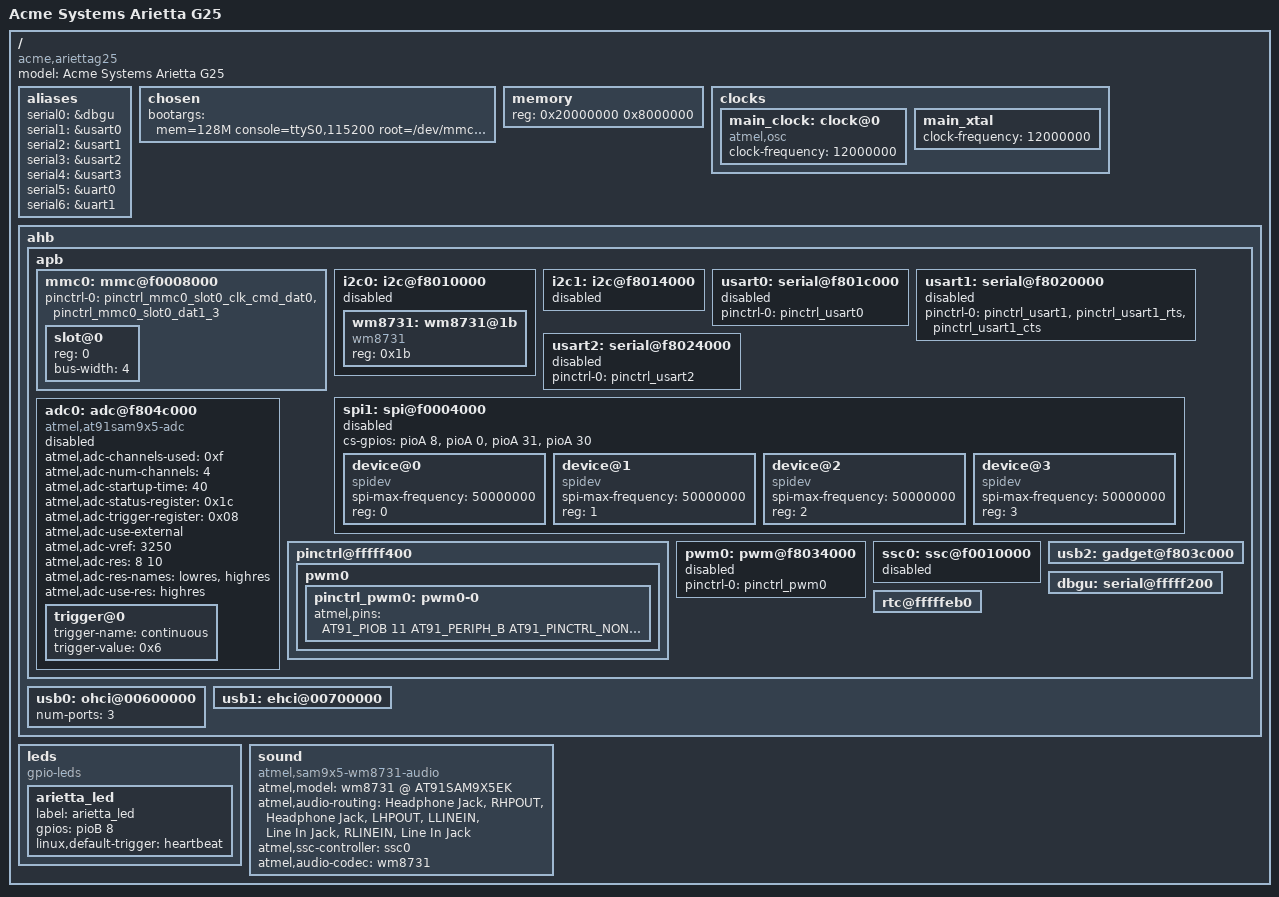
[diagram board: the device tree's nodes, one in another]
/*
 * acme-arietta.dts - Device Tree file for Arietta G25
 * Copyright (C) 2015 Sergio Tanzilli <sergio@tanzilli.com>
 *
 * Licensed under GPLv2 or later. 
 */
/dts-v1/;
#include "at91sam9g25.dtsi"
/ {
	model = "Acme Systems Arietta G25";
	compatible = "acme,ariettag25", "atmel,at91sam9x5ek","atmel,at91sam9x5", "atmel,at91sam9";
	aliases {
		serial0 = &dbgu;
		serial1 = &usart0;
		serial2 = &usart1;
		serial3 = &usart2;
		serial4 = &usart3;
		serial5 = &uart0;
		serial6 = &uart1;
	};

	chosen {
		bootargs = "mem=128M console=ttyS0,115200 root=/dev/mmcblk0p2 rootfstype=ext4 rootwait consoleblank=0";
	};

	memory {
		reg = <0x20000000 0x8000000>;
	};

	clocks {
		#address-cells = <1>;
		#size-cells = <1>;
		ranges;
		main_clock: clock@0 {
			compatible = "atmel,osc", "fixed-clock";
			clock-frequency = <12000000>;
		};

		main_xtal { 
			clock-frequency = <12000000>; 
		}; 
	};

	ahb {
		apb {
			mmc0: mmc@f0008000 {
				pinctrl-0 = <
				  &pinctrl_mmc0_slot0_clk_cmd_dat0
				  &pinctrl_mmc0_slot0_dat1_3>;
				status = "okay";
				slot@0 {
					reg = <0>;
					bus-width = <4>;
				};
			};
			i2c0: i2c@f8010000 {
				status ="disabled";
				wm8731: wm8731@1b {
					compatible = "wm8731";
					reg = <0x1b>;
				};
			};
			i2c1: i2c@f8014000 {
				status ="disabled";
			};
			usart0: serial@f801c000 {
				pinctrl-0 = <&pinctrl_usart0>;
				status ="disabled";
			};
			usart1: serial@f8020000 {
				pinctrl-0 = <&pinctrl_usart1 &pinctrl_usart1_rts &pinctrl_usart1_cts>;
				status ="disabled";
			};
			usart2: serial@f8024000 {
				pinctrl-0 = <&pinctrl_usart2>;
				status ="disabled";
			};
			spi1: spi@f0004000 {
				status = "disabled";
				cs-gpios = <&pioA 8 0>, <&pioA 0 0>, <&pioA 31 0>, <&pioA 30 0>;
				device@0 {
					compatible = "spidev";
					spi-max-frequency = <50000000>;	    // 50 MHz
					reg = <0>;
				};
				device@1 {
					compatible = "spidev";
					spi-max-frequency = <50000000>;	    // 50 MHz
					reg = <1>;
				};
				device@2 {
					compatible = "spidev";
					spi-max-frequency = <50000000>;	    // 50 MHz
					reg = <2>;
				};
				device@3 {
					compatible = "spidev";
					spi-max-frequency = <50000000>;	    // 50 MHz
					reg = <3>;
				};
			};

			adc0: adc@f804c000 {
				status = "disabled";
				atmel,adc-channels-used = <0xf>;
				atmel,adc-num-channels = <4>;
				compatible = "atmel,at91sam9x5-adc";
				atmel,adc-startup-time = <40>;
				atmel,adc-status-register = <0x1c>;
				atmel,adc-trigger-register = <0x08>;
				atmel,adc-use-external;
				atmel,adc-vref = <3250>;
				atmel,adc-res = <8 10>;
				atmel,adc-res-names = "lowres", "highres";
				atmel,adc-use-res = "highres";
				trigger@0 {
					trigger-name = "continuous";
					trigger-value = <0x6>;
				};
			};

			pinctrl@fffff400 {
				pwm0 {
					pinctrl_pwm0: pwm0-0 {
						atmel,pins =
						< AT91_PIOB 11 AT91_PERIPH_B AT91_PINCTRL_NONE
						  AT91_PIOB 12 AT91_PERIPH_B AT91_PINCTRL_NONE
						  AT91_PIOB 13 AT91_PERIPH_B AT91_PINCTRL_NONE
						  AT91_PIOB 14 AT91_PERIPH_B AT91_PINCTRL_NONE >;
					};
				};
			};
			pwm0: pwm@f8034000 {
				pinctrl-names = "default";
				pinctrl-0 = <&pinctrl_pwm0>;
				status = "disabled";
			};

			ssc0: ssc@f0010000 {
				status = "disabled";
			};
			usb2: gadget@f803c000 {
				status = "okay";
			};
			dbgu: serial@fffff200 {
				status = "okay";
			};
			pinctrl@fffff400 {
			};
			rtc@fffffeb0 {
				status = "okay";
			};
		};
		usb0: ohci@00600000 {
			status = "okay";
			num-ports = <3>;
		};
		usb1: ehci@00700000 {
			status = "okay";
		};
	};
	leds {
		compatible = "gpio-leds";
		arietta_led {
			label = "arietta_led";
			gpios = <&pioB 8 GPIO_ACTIVE_HIGH>; /* PB8 */
			linux,default-trigger = "heartbeat";
		};
	};
	sound {
		compatible = "atmel,sam9x5-wm8731-audio";
		atmel,model = "wm8731 @ AT91SAM9X5EK";
		atmel,audio-routing =
		"Headphone Jack", "RHPOUT",
		"Headphone Jack", "LHPOUT",
		"LLINEIN", "Line In Jack",
		"RLINEIN", "Line In Jack";
		atmel,ssc-controller = <&ssc0>;
		atmel,audio-codec = <&wm8731>;
	};

};
